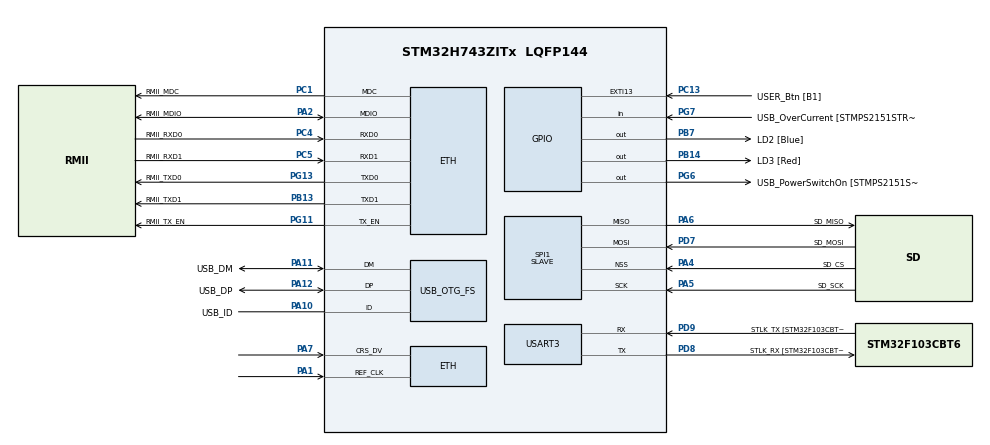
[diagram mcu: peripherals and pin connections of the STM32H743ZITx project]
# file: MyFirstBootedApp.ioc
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Mcu.Family=STM32H7
PD7.Mode=Full_Duplex_Slave
PA6.Mode=Full_Duplex_Slave
RCC.CortexFreq_Value=64000000
PG6.Signal=GPIO_Output
SPI1.VirtualType=VM_SLAVE
PH0-OSC_IN\ (PH0).Signal=RCC_OSC_IN
PB14.GPIO_Label=LD3 [Red]
PG6.GPIO_Label=USB_PowerSwitchOn [STMPS2151STR_EN]
RCC.PLLFRACN=3072
PA11.Mode=OTG/Dual_Role_Device
PA6.GPIO_Label=SD_MISO
RCC.PLL2FRACN=0
PC5.Mode=RMII
PC13.GPIO_Label=USER_Btn [B1]
PB13.GPIO_Label=RMII_TXD1
PB13.Signal=ETH_TXD1
PG13.Signal=ETH_TXD0
PD9.Mode=Asynchronous
PG11.Signal=ETH_TX_EN
ProjectManager.StackSize=0x400
RCC.SPI123CLockSelection=RCC_SPI123CLKSOURCE_CLKP
USART3.VirtualMode-Asynchronous=VM_ASYNC
PA12.Signal=USB_OTG_FS_DP
Mcu.UserConstants=ima_path,"/ima/"
PA4.Mode=NSS_Signal_Hard_Input
SPI1.Direction=SPI_DIRECTION_2LINES
RCC.HCLKFreq_Value=64000000
PD8.Signal=USART3_TX
RCC.DIVM1=4
PC4.GPIO_Label=RMII_RXD0
SPI1.DataSize=SPI_DATASIZE_8BIT
PA10.GPIO_Label=USB_ID
PB7.Signal=GPIO_Output
PA8.Signal=USB_OTG_FS_SOF
SPI1.VirtualNSS=VM_NSSHARD
PG13.Mode=RMII
PB7.PinState=GPIO_PIN_RESET
PD7.GPIO_Label=SD_MOSI
RCC.APB3Freq_Value=64000000
PB7.GPIO_Label=LD2 [Blue]
Mcu.Package=LQFP144
PA6.Signal=SPI1_MISO
RCC.PLL3FRACN=0
PA2.GPIO_Label=RMII_MDIO
PA10.Signal=USB_OTG_FS_ID
RCC.APB4Freq_Value=64000000
PG11.GPIO_Label=RMII_TX_EN
PC5.Signal=ETH_RXD1
PB13.Mode=RMII
PA4.GPIO_Label=SD_CS
PC4.Mode=RMII
PA5.Mode=Full_Duplex_Slave
RCC.PLLSourceVirtual=RCC_PLLSOURCE_HSI
RCC.DIVQ1=3
PA7.Mode=RMII
PG7.Signal=GPIO_Input
PD9.GPIO_Label=STLK_TX [STM32F103CBT6_PA2]
PA10.Mode=OTG/Dual_Role_Device
PC13.Signal=GPXTI13
PA9.GPIO_Label=USB_VBUS
PC4.Signal=ETH_RXD0
PD7.Signal=SPI1_MOSI
PA11.GPIO_Label=USB_DM
RCC.D2PPRE1=RCC_APB1_DIV2
PD9.Signal=USART3_RX
PG13.GPIO_Label=RMII_TXD0
PA12.GPIO_Label=USB_DP
PD8.GPIO_Label=STLK_RX [STM32F103CBT6_PA3]
PA8.GPIO_Label=USB_SOF [TP1]
ProjectManager.TargetToolchain=STM32CubeIDE
PC15-OSC32_OUT\ (OSC32_OUT).Signal=RCC_OSC32_OUT
PA9.Signal=USB_OTG_FS_VBUS
RCC.DIVN1=9
RCC.USBFreq_Value=48000000
PD8.Mode=Asynchronous
PA1.Signal=ETH_REF_CLK
VP_FATFS_VS_Generic.Mode=User_defined
PB14.Signal=GPIO_Output
RCC.USBCLockSelection=RCC_USBCLKSOURCE_HSI48
PA5.Signal=SPI1_SCK
board=NUCLEO-H743ZI
RCC.APB2Freq_Value=64000000
PA1.Mode=RMII
SPI1.CRCCalculation=SPI_CRCCALCULATION_ENABLE
SPI1.Mode=SPI_MODE_SLAVE
PG7.GPIO_Label=USB_OverCurrent [STMPS2151STR_FAULT]
RCC.ADCFreq_Value=129000000
PC1.GPIO_Label=RMII_MDC
Mcu.Name=STM32H743ZITx
PA2.Signal=ETH_MDIO
FATFS._MAX_SS=4096
PA4.Signal=SPI1_NSS
RCC.SYSCLKFreq_VALUE=64000000
ETH.MediaInterface=HAL_ETH_RMII_MODE
PA12.Mode=OTG/Dual_Role_Device
PA5.GPIO_Label=SD_SCK
PC14-OSC32_IN\ (OSC32_IN).Signal=RCC_OSC32_IN
PC5.GPIO_Label=RMII_RXD1
PG11.Mode=RMII
PA11.Signal=USB_OTG_FS_DM
ProjectManager.HeapSize=0x200
NVIC.PriorityGroup=NVIC_PRIORITYGROUP_4
PH0-OSC_IN\ (PH0).GPIO_Label=MCO
PA2.Mode=RMII
RCC.APB1Freq_Value=32000000
PC1.Signal=ETH_MDC
PC1.Mode=RMII
PA7.Signal=ETH_CRS_DV

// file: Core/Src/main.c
/* USER CODE BEGIN Header */
/**
  ******************************************************************************
  * @file           : main.c
  * @brief          : Main program body
  ******************************************************************************
  * @attention
  *
  * <h2><center>&copy; Copyright (c) 2021 STMicroelectronics.
  * All rights reserved.</center></h2>
  *
  * This software component is licensed by ST under BSD 3-Clause license,
  * the "License"; You may not use this file except in compliance with the
  * License. You may obtain a copy of the License at:
  *                        opensource.org/licenses/BSD-3-Clause
  *
  ******************************************************************************
  */
/* USER CODE END Header */
#include "main.h"
#include "string.h"
#include "fatfs.h"

/* USER CODE BEGIN Includes */
#include <stdio.h>
#include <string.h>
#include <stdarg.h> 		//for va_list var arg functions
#include <image_hdr.h>
#include <crc32.h>

/* USER CODE END Includes */

/* USER CODE BEGIN PTD */
typedef void (*ptrF)(void);
/* USER CODE END PTD */

#if defined ( __ICCARM__ ) /*!< IAR Compiler */

#pragma location=0x30040000
ETH_DMADescTypeDef  DMARxDscrTab[ETH_RX_DESC_CNT]; /* Ethernet Rx DMA Descriptors */
#pragma location=0x30040060
ETH_DMADescTypeDef  DMATxDscrTab[ETH_TX_DESC_CNT]; /* Ethernet Tx DMA Descriptors */
#pragma location=0x30040200
uint8_t Rx_Buff[ETH_RX_DESC_CNT][ETH_MAX_PACKET_SIZE]; /* Ethernet Receive Buffers */

#elif defined ( __CC_ARM )  /* MDK ARM Compiler */

__attribute__((at(0x30040000))) ETH_DMADescTypeDef  DMARxDscrTab[ETH_RX_DESC_CNT]; /* Ethernet Rx DMA Descriptors */
__attribute__((at(0x30040060))) ETH_DMADescTypeDef  DMATxDscrTab[ETH_TX_DESC_CNT]; /* Ethernet Tx DMA Descriptors */
__attribute__((at(0x30040200))) uint8_t Rx_Buff[ETH_RX_DESC_CNT][ETH_MAX_PACKET_SIZE]; /* Ethernet Receive Buffer */

#elif defined ( __GNUC__ ) /* GNU Compiler */

ETH_DMADescTypeDef DMARxDscrTab[ETH_RX_DESC_CNT] __attribute__((section(".RxDecripSection"))); /* Ethernet Rx DMA Descriptors */
ETH_DMADescTypeDef DMATxDscrTab[ETH_TX_DESC_CNT] __attribute__((section(".TxDecripSection")));   /* Ethernet Tx DMA Descriptors */
uint8_t Rx_Buff[ETH_RX_DESC_CNT][ETH_MAX_PACKET_SIZE] __attribute__((section(".RxArraySection"))); /* Ethernet Receive Buffers */

#endif

ETH_TxPacketConfig TxConfig;

ETH_HandleTypeDef heth;

SPI_HandleTypeDef hspi1;

UART_HandleTypeDef huart3;

void SystemClock_Config(void);
void PeriphCommonClock_Config(void);
static void MX_GPIO_Init(void);
static void MX_SPI1_Init(void);
static void MX_USART3_UART_Init(void);
static void MX_ETH_Init(void);
static void MX_USB_OTG_FS_USB_Init(void);

int app_main(void)
{

  /* MCU Configuration--------------------------------------------------------*/

  /* Reset of all peripherals, Initializes the Flash interface and the Systick. */
  HAL_Init();

  /* Configure the system clock */
  SystemClock_Config();

/* Configure the peripherals common clocks */
  PeriphCommonClock_Config();

  /* Initialize all configured peripherals */
  MX_GPIO_Init();
  MX_SPI1_Init();
  MX_FATFS_Init();
  MX_USART3_UART_Init();
  MX_ETH_Init();
  MX_USB_OTG_FS_USB_Init();
  /* USER CODE BEGIN 2 */
  image_hdr_t *image_hdr = (image_hdr_t *) &(__IMAGE_HDR_START__);
  uint32_t crc = image_hdr->crc;

//	// compute CRC of the programmed area
//  uint32_t sum = 0;
//
//	//pass all the flash memory addresses. //Start address is 0x08020000 (for this controller)
//	// TODO: Pass the starting flash address as parameter.
//  uint32_t flash_prog_start_add = 0x08020000 | 0x200; 		//512 is image_hdr memory space.
//
//  for (uint32_t p = 0; p < image_hdr->data_size; p += 4) {
//	  uint32_t bytes;
//
//	  uint32_t address = flash_prog_start_add + p;
//	  if(address & 3)
//	  {
//		  return 0;
//	  }
//
////		if ((p == 0) && (first_word != 0xffffffff)) {
////			bytes = first_word;
////
////		} else {
////			bytes = flash_func_read_word(p);
////		}
//
//	  //get data from flash
//	  bytes = *(uint32_t *) address;
//
//	  sum = crc32((uint8_t *)&bytes, sizeof(bytes), sum);
//  }
//
//  if(crc != sum)
//  {
//	  printf("Error. Flash memory data corruption");
//  }
//
//
//  //myprintf("\r\n~ SD card demo by kiwih ~\r\n\r\n");
//
//  HAL_Delay(1000); //a short delay is important to let the SD card settle
//
//  //some variables for FatFs
//  FATFS FatFs; 	//Fatfs handle
//  FIL fil; 		//File handle
//  FRESULT fres; //Result after operations
//
//  //Open the file system
//  fres = f_mount(&FatFs, "", 1); //1=mount now
//  if (fres != FR_OK) {
//	printf("f_mount error (%i)\r\n", fres);
//	while(1);
//  }
//
//  //Let's get some statistics from the SD card
//  DWORD free_clusters, free_sectors, total_sectors;
//
//  FATFS* getFreeFs;
//
//  fres = f_getfree("", &free_clusters, &getFreeFs);
//  if (fres != FR_OK) {
//	printf("f_getfree error (%i)\r\n", fres);
//	while(1);
//  }
//
//  //Formula comes from ChaN's documentation
//  total_sectors = (getFreeFs->n_fatent - 2) * getFreeFs->csize;
//  free_sectors = free_clusters * getFreeFs->csize;
//
////  myprintf("SD card stats:\r\n%10lu KiB total drive space.\r\n%10lu KiB available.\r\n", total_sectors / 2, free_sectors / 2);
//
//  //Now let's try to open file "test.txt"
//  fres = f_open(&fil, "test.txt", FA_READ);
//  if (fres != FR_OK) {
////	printf("f_open error (%i)\r\n");
//	while(1);
//  }
////  myprintf("I was able to open 'test.txt' for reading!\r\n");
//
//  //Read 30 bytes from "test.txt" on the SD card
//  BYTE readBuf[30];
//
//  //We can either use f_read OR f_gets to get data out of files
//  //f_gets is a wrapper on f_read that does some string formatting for us
//  TCHAR* rres = f_gets((TCHAR*)readBuf, 30, &fil);
//  if(rres != 0) {
////	myprintf("Read string from 'test.txt' contents: %s\r\n", readBuf);
//  } else {
////	myprintf("f_gets error (%i)\r\n", fres);
//  }
//
//  //Be a tidy kiwi - don't forget to close your file!
//  f_close(&fil);
//
//  //Now let's try and write a file "write.txt"
//  fres = f_open(&fil, "write.txt", FA_WRITE | FA_OPEN_ALWAYS | FA_CREATE_ALWAYS);
//  if(fres == FR_OK) {
//	printf("I was able to open 'write.txt' for writing\r\n");
//  } else {
//	printf("f_open error (%i)\r\n", fres);
//  }
//
//  //Copy in a string
//  char message[] = "a new file is made!";
//  strncpy((char*)readBuf, message, strlen(message));
//  UINT bytesWrote;
//  fres = f_write(&fil, readBuf, 19, &bytesWrote);
//  if(fres == FR_OK) {
//	printf("Wrote %i bytes to 'write.txt'!\r\n", bytesWrote);
//  } else {
////	printf("f_write error (%i)\r\n");
//  }
//
//  //Be a tidy kiwi - don't forget to close your file!
//  f_close(&fil);
//
//  //We're done, so de-mount the drive
//  f_mount(NULL, "", 0);

  /* USER CODE END 2 */

  /* Infinite loop */
  while (1)
  {

    /* USER CODE BEGIN 3 */
      //Blink the LED every second
	  HAL_GPIO_TogglePin(LD2_GPIO_Port, LD2_Pin);		//Blue LED
	  HAL_GPIO_TogglePin(LD3_GPIO_Port, LD3_Pin);
	  HAL_Delay(1000);
  }
  /* USER CODE END 3 */
}

void SystemClock_Config(void)
{
  RCC_OscInitTypeDef RCC_OscInitStruct = {0};
  RCC_ClkInitTypeDef RCC_ClkInitStruct = {0};

  /** Supply configuration update enable
  */
  HAL_PWREx_ConfigSupply(PWR_LDO_SUPPLY);
  /** Configure the main internal regulator output voltage
  */
  __HAL_PWR_VOLTAGESCALING_CONFIG(PWR_REGULATOR_VOLTAGE_SCALE3);

  while(!__HAL_PWR_GET_FLAG(PWR_FLAG_VOSRDY)) {}
  /** Initializes the RCC Oscillators according to the specified parameters
  * in the RCC_OscInitTypeDef structure.
  */
  RCC_OscInitStruct.OscillatorType = RCC_OSCILLATORTYPE_HSI48|RCC_OSCILLATORTYPE_HSI;
  RCC_OscInitStruct.HSIState = RCC_HSI_DIV1;
  RCC_OscInitStruct.HSICalibrationValue = RCC_HSICALIBRATION_DEFAULT;
  RCC_OscInitStruct.HSI48State = RCC_HSI48_ON;
  RCC_OscInitStruct.PLL.PLLState = RCC_PLL_NONE;
  if (HAL_RCC_OscConfig(&RCC_OscInitStruct) != HAL_OK)
  {
    Error_Handler();
  }
  /** Initializes the CPU, AHB and APB buses clocks
  */
  RCC_ClkInitStruct.ClockType = RCC_CLOCKTYPE_HCLK|RCC_CLOCKTYPE_SYSCLK
                              |RCC_CLOCKTYPE_PCLK1|RCC_CLOCKTYPE_PCLK2
                              |RCC_CLOCKTYPE_D3PCLK1|RCC_CLOCKTYPE_D1PCLK1;
  RCC_ClkInitStruct.SYSCLKSource = RCC_SYSCLKSOURCE_HSI;
  RCC_ClkInitStruct.SYSCLKDivider = RCC_SYSCLK_DIV1;
  RCC_ClkInitStruct.AHBCLKDivider = RCC_HCLK_DIV1;
  RCC_ClkInitStruct.APB3CLKDivider = RCC_APB3_DIV1;
  RCC_ClkInitStruct.APB1CLKDivider = RCC_APB1_DIV2;
  RCC_ClkInitStruct.APB2CLKDivider = RCC_APB2_DIV1;
  RCC_ClkInitStruct.APB4CLKDivider = RCC_APB4_DIV1;

  if (HAL_RCC_ClockConfig(&RCC_ClkInitStruct, FLASH_LATENCY_1) != HAL_OK)
  {
    Error_Handler();
  }
}

void PeriphCommonClock_Config(void)
{
  RCC_PeriphCLKInitTypeDef PeriphClkInitStruct = {0};

  /** Initializes the peripherals clock
  */
  PeriphClkInitStruct.PeriphClockSelection = RCC_PERIPHCLK_CKPER;
  PeriphClkInitStruct.CkperClockSelection = RCC_CLKPSOURCE_HSI;
  if (HAL_RCCEx_PeriphCLKConfig(&PeriphClkInitStruct) != HAL_OK)
  {
    Error_Handler();
  }
}

static void MX_ETH_Init(void)
{

  heth.Instance = ETH;
  heth.Init.MACAddr[0] =   0x00;
  heth.Init.MACAddr[1] =   0x80;
  heth.Init.MACAddr[2] =   0xE1;
  heth.Init.MACAddr[3] =   0x00;
  heth.Init.MACAddr[4] =   0x00;
  heth.Init.MACAddr[5] =   0x00;
  heth.Init.MediaInterface = HAL_ETH_RMII_MODE;
  heth.Init.TxDesc = DMATxDscrTab;
  heth.Init.RxDesc = DMARxDscrTab;
  heth.Init.RxBuffLen = 1524;

  if (HAL_ETH_Init(&heth) != HAL_OK)
  {
    Error_Handler();
  }

  memset(&TxConfig, 0 , sizeof(ETH_TxPacketConfig));
  TxConfig.Attributes = ETH_TX_PACKETS_FEATURES_CSUM | ETH_TX_PACKETS_FEATURES_CRCPAD;
  TxConfig.ChecksumCtrl = ETH_CHECKSUM_IPHDR_PAYLOAD_INSERT_PHDR_CALC;
  TxConfig.CRCPadCtrl = ETH_CRC_PAD_INSERT;

}

static void MX_SPI1_Init(void)
{

  /* SPI1 parameter configuration*/
  hspi1.Instance = SPI1;
  hspi1.Init.Mode = SPI_MODE_SLAVE;
  hspi1.Init.Direction = SPI_DIRECTION_2LINES;
  hspi1.Init.DataSize = SPI_DATASIZE_8BIT;
  hspi1.Init.CLKPolarity = SPI_POLARITY_LOW;
  hspi1.Init.CLKPhase = SPI_PHASE_1EDGE;
  hspi1.Init.NSS = SPI_NSS_HARD_INPUT;
  hspi1.Init.FirstBit = SPI_FIRSTBIT_MSB;
  hspi1.Init.TIMode = SPI_TIMODE_DISABLE;
  hspi1.Init.CRCCalculation = SPI_CRCCALCULATION_ENABLE;
  hspi1.Init.CRCPolynomial = 0x107;
  hspi1.Init.CRCLength = SPI_CRC_LENGTH_DATASIZE;
  hspi1.Init.NSSPMode = SPI_NSS_PULSE_DISABLE;
  hspi1.Init.NSSPolarity = SPI_NSS_POLARITY_LOW;
  hspi1.Init.FifoThreshold = SPI_FIFO_THRESHOLD_01DATA;
  hspi1.Init.TxCRCInitializationPattern = SPI_CRC_INITIALIZATION_ALL_ZERO_PATTERN;
  hspi1.Init.RxCRCInitializationPattern = SPI_CRC_INITIALIZATION_ALL_ZERO_PATTERN;
  hspi1.Init.MasterSSIdleness = SPI_MASTER_SS_IDLENESS_00CYCLE;
  hspi1.Init.MasterInterDataIdleness = SPI_MASTER_INTERDATA_IDLENESS_00CYCLE;
  hspi1.Init.MasterReceiverAutoSusp = SPI_MASTER_RX_AUTOSUSP_DISABLE;
  hspi1.Init.MasterKeepIOState = SPI_MASTER_KEEP_IO_STATE_DISABLE;
  hspi1.Init.IOSwap = SPI_IO_SWAP_DISABLE;
  if (HAL_SPI_Init(&hspi1) != HAL_OK)
  {
    Error_Handler();
  }

}

static void MX_USART3_UART_Init(void)
{

  huart3.Instance = USART3;
  huart3.Init.BaudRate = 115200;
  huart3.Init.WordLength = UART_WORDLENGTH_8B;
  huart3.Init.StopBits = UART_STOPBITS_1;
  huart3.Init.Parity = UART_PARITY_NONE;
  huart3.Init.Mode = UART_MODE_TX_RX;
  huart3.Init.HwFlowCtl = UART_HWCONTROL_NONE;
  huart3.Init.OverSampling = UART_OVERSAMPLING_16;
  huart3.Init.OneBitSampling = UART_ONE_BIT_SAMPLE_DISABLE;
  huart3.Init.ClockPrescaler = UART_PRESCALER_DIV1;
  huart3.AdvancedInit.AdvFeatureInit = UART_ADVFEATURE_NO_INIT;
  if (HAL_UART_Init(&huart3) != HAL_OK)
  {
    Error_Handler();
  }
  if (HAL_UARTEx_SetTxFifoThreshold(&huart3, UART_TXFIFO_THRESHOLD_1_8) != HAL_OK)
  {
    Error_Handler();
  }
  if (HAL_UARTEx_SetRxFifoThreshold(&huart3, UART_RXFIFO_THRESHOLD_1_8) != HAL_OK)
  {
    Error_Handler();
  }
  if (HAL_UARTEx_DisableFifoMode(&huart3) != HAL_OK)
  {
    Error_Handler();
  }

}

static void MX_USB_OTG_FS_USB_Init(void)
{

}

static void MX_GPIO_Init(void)
{
  GPIO_InitTypeDef GPIO_InitStruct = {0};

  /* GPIO Ports Clock Enable */
  __HAL_RCC_GPIOC_CLK_ENABLE();
  __HAL_RCC_GPIOH_CLK_ENABLE();
  __HAL_RCC_GPIOA_CLK_ENABLE();
  __HAL_RCC_GPIOB_CLK_ENABLE();
  __HAL_RCC_GPIOD_CLK_ENABLE();
  __HAL_RCC_GPIOG_CLK_ENABLE();

  /*Configure GPIO pin Output Level */
  HAL_GPIO_WritePin(GPIOB, LD3_Pin|LD2_Pin, GPIO_PIN_RESET);

  /*Configure GPIO pin Output Level */
  HAL_GPIO_WritePin(USB_PowerSwitchOn_GPIO_Port, USB_PowerSwitchOn_Pin, GPIO_PIN_RESET);

  /*Configure GPIO pin : USER_Btn_Pin */
  GPIO_InitStruct.Pin = USER_Btn_Pin;
  GPIO_InitStruct.Mode = GPIO_MODE_IT_RISING;
  GPIO_InitStruct.Pull = GPIO_NOPULL;
  HAL_GPIO_Init(USER_Btn_GPIO_Port, &GPIO_InitStruct);

  /*Configure GPIO pins : LD3_Pin LD2_Pin */
  GPIO_InitStruct.Pin = LD3_Pin|LD2_Pin;
  GPIO_InitStruct.Mode = GPIO_MODE_OUTPUT_PP;
  GPIO_InitStruct.Pull = GPIO_NOPULL;
  GPIO_InitStruct.Speed = GPIO_SPEED_FREQ_LOW;
  HAL_GPIO_Init(GPIOB, &GPIO_InitStruct);

  /*Configure GPIO pin : USB_PowerSwitchOn_Pin */
  GPIO_InitStruct.Pin = USB_PowerSwitchOn_Pin;
  GPIO_InitStruct.Mode = GPIO_MODE_OUTPUT_PP;
  GPIO_InitStruct.Pull = GPIO_NOPULL;
  GPIO_InitStruct.Speed = GPIO_SPEED_FREQ_LOW;
  HAL_GPIO_Init(USB_PowerSwitchOn_GPIO_Port, &GPIO_InitStruct);

  /*Configure GPIO pin : USB_OverCurrent_Pin */
  GPIO_InitStruct.Pin = USB_OverCurrent_Pin;
  GPIO_InitStruct.Mode = GPIO_MODE_INPUT;
  GPIO_InitStruct.Pull = GPIO_NOPULL;
  HAL_GPIO_Init(USB_OverCurrent_GPIO_Port, &GPIO_InitStruct);

  /*Configure GPIO pins : USB_SOF_Pin USB_ID_Pin USB_DM_Pin USB_DP_Pin */
  GPIO_InitStruct.Pin = USB_SOF_Pin|USB_ID_Pin|USB_DM_Pin|USB_DP_Pin;
  GPIO_InitStruct.Mode = GPIO_MODE_AF_PP;
  GPIO_InitStruct.Pull = GPIO_NOPULL;
  GPIO_InitStruct.Speed = GPIO_SPEED_FREQ_LOW;
  GPIO_InitStruct.Alternate = GPIO_AF10_OTG1_FS;
  HAL_GPIO_Init(GPIOA, &GPIO_InitStruct);

}

void Error_Handler(void)
{
  __disable_irq();
  while (1)
  {
  }
}

/************************ (C) COPYRIGHT STMicroelectronics *****END OF FILE****/
